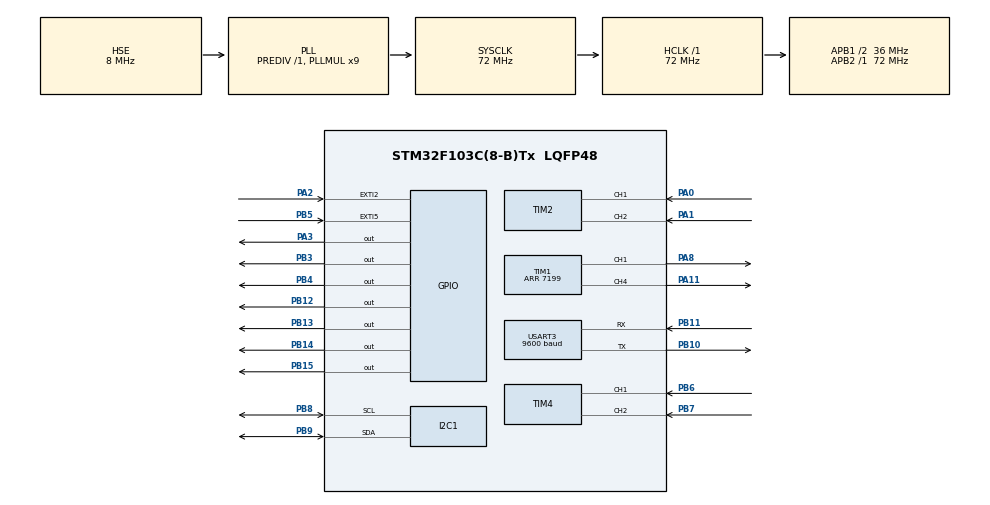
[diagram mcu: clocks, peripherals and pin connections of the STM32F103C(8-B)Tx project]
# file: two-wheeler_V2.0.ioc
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FREERTOS.Tasks01=defaultTask,24,128,StartDefaultTask,Default,NULL,Dynamic,NULL,NULL
FREERTOS.configTOTAL_HEAP_SIZE=10000
Mcu.Family=STM32F1
Mcu.Name=STM32F103C(8-B)Tx
Mcu.Package=LQFP48
NVIC.EXTI2_IRQn=true\:5\:0\:false\:false\:true\:true\:true\:true\:true
NVIC.EXTI9_5_IRQn=true\:5\:0\:false\:false\:true\:true\:true\:true\:true
NVIC.PriorityGroup=NVIC_PRIORITYGROUP_4
NVIC.TIM3_IRQn=true\:15\:0\:false\:false\:true\:false\:false\:true\:true
NVIC.TimeBase=TIM3_IRQn
NVIC.TimeBaseIP=TIM3
NVIC.USART3_IRQn=true\:5\:0\:false\:false\:true\:true\:true\:true\:true
PA0-WKUP.Signal=S_TIM2_CH1_ETR
PA1.Signal=S_TIM2_CH2
PA11.Signal=S_TIM1_CH4
PA13.Mode=Serial_Wire
PA13.Signal=SYS_JTMS-SWDIO
PA14.Mode=Serial_Wire
PA14.Signal=SYS_JTCK-SWCLK
PA2.GPIO_ModeDefaultEXTI=GPIO_MODE_IT_RISING_FALLING
PA2.Signal=GPXTI2
PA3.GPIO_Speed=GPIO_SPEED_FREQ_HIGH
PA3.Signal=GPIO_Output
PA8.Signal=S_TIM1_CH1
PB10.Mode=Asynchronous
PB10.Signal=USART3_TX
PB11.Mode=Asynchronous
PB11.Signal=USART3_RX
PB12.Signal=GPIO_Output
PB13.Signal=GPIO_Output
PB14.Signal=GPIO_Output
PB15.Signal=GPIO_Output
PB3.Signal=GPIO_Output
PB4.Signal=GPIO_Output
PB5.GPIO_ModeDefaultEXTI=GPIO_MODE_IT_FALLING
PB5.Signal=GPXTI5
PB6.Signal=S_TIM4_CH1
PB7.Signal=S_TIM4_CH2
PB8.Mode=I2C
PB8.Signal=I2C1_SCL
PB9.Mode=I2C
PB9.Signal=I2C1_SDA
PC14-OSC32_IN.Mode=LSE-External-Oscillator
PC14-OSC32_IN.Signal=RCC_OSC32_IN
PC15-OSC32_OUT.Mode=LSE-External-Oscillator
PC15-OSC32_OUT.Signal=RCC_OSC32_OUT
PD0-OSC_IN.Mode=HSE-External-Oscillator
PD0-OSC_IN.Signal=RCC_OSC_IN
PD1-OSC_OUT.Mode=HSE-External-Oscillator
PD1-OSC_OUT.Signal=RCC_OSC_OUT
ProjectManager.HeapSize=0x200
ProjectManager.StackSize=0x400
ProjectManager.TargetToolchain=MDK-ARM V5.32
RCC.AHBFreq_Value=72000000
RCC.APB1CLKDivider=RCC_HCLK_DIV2
RCC.APB1Freq_Value=36000000
RCC.APB1TimFreq_Value=72000000
RCC.APB2Freq_Value=72000000
RCC.APB2TimFreq_Value=72000000
RCC.HCLKFreq_Value=72000000
RCC.PLLMUL=RCC_PLL_MUL9
RCC.PLLSourceVirtual=RCC_PLLSOURCE_HSE
RCC.SYSCLKFreq_VALUE=72000000
RCC.SYSCLKSource=RCC_SYSCLKSOURCE_PLLCLK
RCC.USBFreq_Value=72000000
SH.S_TIM1_CH1.0=TIM1_CH1,PWM Generation1 CH1
SH.S_TIM1_CH4.0=TIM1_CH4,PWM Generation4 CH4
SH.S_TIM2_CH1_ETR.0=TIM2_CH1,Encoder_Interface
SH.S_TIM2_CH2.0=TIM2_CH2,Encoder_Interface
SH.S_TIM4_CH1.0=TIM4_CH1,Encoder_Interface
SH.S_TIM4_CH2.0=TIM4_CH2,Encoder_Interface
TIM1.Channel-PWM\ Generation1\ CH1=TIM_CHANNEL_1
TIM1.Channel-PWM\ Generation4\ CH4=TIM_CHANNEL_4
TIM1.Period=7199
TIM1.Pulse-PWM\ Generation1\ CH1=7200
TIM2.EncoderMode=TIM_ENCODERMODE_TI12
TIM4.EncoderMode=TIM_ENCODERMODE_TI12
USART3.BaudRate=9600
USART3.VirtualMode=VM_ASYNC
VP_FREERTOS_VS_CMSIS_V2.Mode=CMSIS_V2
VP_SYS_VS_tim3.Mode=TIM3
board=custom

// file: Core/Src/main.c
/* USER CODE BEGIN Header */
/**
  ******************************************************************************
  * @file           : main.c
  * @brief          : Main program body
  ******************************************************************************
  * @attention
  *
  * Copyright (c) 2025 STMicroelectronics.
  * All rights reserved.
  *
  * This software is licensed under terms that can be found in the LICENSE file
  * in the root directory of this software component.
  * If no LICENSE file comes with this software, it is provided AS-IS.
  *
  ******************************************************************************
  */
/* USER CODE END Header */
#include "main.h"
#include "cmsis_os.h"
#include "i2c.h"
#include "tim.h"
#include "usart.h"
#include "gpio.h"

/* USER CODE BEGIN Includes */
#include "task_init.h"
#include "sr04.h"

/* USER CODE END Includes */

void SystemClock_Config(void);
void MX_FREERTOS_Init(void);

int main(void)
{

  /* MCU Configuration--------------------------------------------------------*/

  /* Reset of all peripherals, Initializes the Flash interface and the Systick. */
  HAL_Init();

  /* Configure the system clock */
  SystemClock_Config();

  /* Initialize all configured peripherals */
  MX_GPIO_Init();
  MX_I2C1_Init();
  MX_TIM1_Init();
  MX_TIM2_Init();
  MX_TIM4_Init();
  MX_USART3_UART_Init();
  /* USER CODE BEGIN 2 */
  SR04_Init();
	Task_Init();

  /* USER CODE END 2 */

  /* Init scheduler */
  osKernelInitialize();

  /* Call init function for freertos objects (in cmsis_os2.c) */
  MX_FREERTOS_Init();

  /* Start scheduler */
  osKernelStart();

  /* We should never get here as control is now taken by the scheduler */

  /* Infinite loop */
  while (1)
  {

  }
}

void SystemClock_Config(void)
{
  RCC_OscInitTypeDef RCC_OscInitStruct = {0};
  RCC_ClkInitTypeDef RCC_ClkInitStruct = {0};

  /** Initializes the RCC Oscillators according to the specified parameters
  * in the RCC_OscInitTypeDef structure.
  */
  RCC_OscInitStruct.OscillatorType = RCC_OSCILLATORTYPE_HSE;
  RCC_OscInitStruct.HSEState = RCC_HSE_ON;
  RCC_OscInitStruct.HSEPredivValue = RCC_HSE_PREDIV_DIV1;
  RCC_OscInitStruct.HSIState = RCC_HSI_ON;
  RCC_OscInitStruct.PLL.PLLState = RCC_PLL_ON;
  RCC_OscInitStruct.PLL.PLLSource = RCC_PLLSOURCE_HSE;
  RCC_OscInitStruct.PLL.PLLMUL = RCC_PLL_MUL9;
  if (HAL_RCC_OscConfig(&RCC_OscInitStruct) != HAL_OK)
  {
    Error_Handler();
  }

  /** Initializes the CPU, AHB and APB buses clocks
  */
  RCC_ClkInitStruct.ClockType = RCC_CLOCKTYPE_HCLK|RCC_CLOCKTYPE_SYSCLK
                              |RCC_CLOCKTYPE_PCLK1|RCC_CLOCKTYPE_PCLK2;
  RCC_ClkInitStruct.SYSCLKSource = RCC_SYSCLKSOURCE_PLLCLK;
  RCC_ClkInitStruct.AHBCLKDivider = RCC_SYSCLK_DIV1;
  RCC_ClkInitStruct.APB1CLKDivider = RCC_HCLK_DIV2;
  RCC_ClkInitStruct.APB2CLKDivider = RCC_HCLK_DIV1;

  if (HAL_RCC_ClockConfig(&RCC_ClkInitStruct, FLASH_LATENCY_2) != HAL_OK)
  {
    Error_Handler();
  }
}

void HAL_TIM_PeriodElapsedCallback(TIM_HandleTypeDef *htim)
{
  if (htim->Instance == TIM3) {
    HAL_IncTick();
  }
}

void Error_Handler(void)
{
  __disable_irq();
  while (1)
  {
  }
}

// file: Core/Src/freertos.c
/* USER CODE BEGIN Header */
/**
  ******************************************************************************
  * File Name          : freertos.c
  * Description        : Code for freertos applications
  ******************************************************************************
  * @attention
  *
  * Copyright (c) 2025 STMicroelectronics.
  * All rights reserved.
  *
  * This software is licensed under terms that can be found in the LICENSE file
  * in the root directory of this software component.
  * If no LICENSE file comes with this software, it is provided AS-IS.
  *
  ******************************************************************************
  */
/* USER CODE END Header */

#include "FreeRTOS.h"
#include "task.h"
#include "main.h"
#include "cmsis_os.h"

/* USER CODE BEGIN Includes */
#include <stdio.h>
#include "oled.h"
#include "mpu6050.h"
#include "inv_mpu.h"
#include "inv_mpu_dmp_motion_driver.h"
#include "struct.h"

/* USER CODE END Includes */

/* Definitions for defaultTask */
osThreadId_t defaultTaskHandle;
const osThreadAttr_t defaultTask_attributes = {
  .name = "defaultTask",
  .stack_size = 128 * 4,
  .priority = (osPriority_t) osPriorityNormal,
};

void StartDefaultTask(void *argument);

void MX_FREERTOS_Init(void); /* (MISRA C 2004 rule 8.1) */

void MX_FREERTOS_Init(void) {

  /* Create the thread(s) */
  /* creation of defaultTask */
  defaultTaskHandle = osThreadNew(StartDefaultTask, NULL, &defaultTask_attributes);

}

void StartDefaultTask(void *argument)
{
  for(;;)
  {
    osDelay(1);
  }
}
